# ATSAMRH71F20B register map
Vendor: Microchip Technology; Series: SAMRH71; File version: 0
Microchip ATSAMRH71F20B Microcontroller
CPU: CM7 r1p1, little endian, MPU, FPU, 3 interrupt priority bits
Registers are 32-bit, read-write, reset 0x0 unless marked. A register's access mark holds for its fields unless they carry their own. Offsets are from the block's base; lines under a group give offsets from that group; [hi:lo] are bit positions; {n}, {i} and the like mark numbered series; 'fields as' and 'values as' point back to an identical list; <NAME> marks a mode.

## Memory map
0x00000000 LOCKBIT size 0x4
0x40000000 MATRIX0 size 0x2CC — AHB Bus Matrix
0x40004000 HEFC size 0x194 — Harden Embedded Flash Controller
0x40008000 PIOA size 0x5E8 — Parallel Input/Output Controller
0x40008040 PIOB size 0x5E8
0x40008080 PIOC size 0x5E8
0x400080C0 PIOD size 0x5E8
0x40008100 PIOE size 0x5E8
0x40008140 PIOF size 0x5E8
0x40008180 PIOG size 0x5E8
0x4000C000 PMC size 0x1B8 — Power Management Controller
0x40010000 FLEXCOM0 size 0x6EC — Flexible Serial Communication
{0x40010000+0x4000*n} FLEXCOM{n} size 0x6EC (n=1..9)
0x40038000 QSPI size 0xEC — Quad Serial Peripheral Interface
0x4003C000 IP1553 size 0x54
0x40040000 SPW size 0xF0C
0x40058000 MCAN0 size 0xFC — Controller Area Network
0x4005C000 MCAN1 size 0xFC
0x40068000 PWM0 size 0x464 — Pulse Width Modulation Controller
0x4006C000 PWM1 size 0x464
0x40070000 TC0 size 0xE8 — Timer Counter
0x40074000 TC1 size 0xE8
0x40078000 TC2 size 0xE8
0x4007C000 TC3 size 0xE8
0x40080000 HEMC size 0x194
0x40081000 HSMC size 0x78 — Harden Static Memory Controller
0x40082000 HSDRAMC size 0x30 — Hardened SDRAM Controller
0x4008C000 ICM size 0xEC — Integrity Check Monitor
0x40090000 TRNG size 0x54 — True Random Number Generator
0x40094000 SHA size 0xEC — Secure Hash Algorithm
0x40098000 XDMAC size 0x13D8 — Extensible DMA Controller
0x4009C000 GMAC size 0x820 — Gigabit Ethernet MAC
0x400A0000 SFR size 0xA8 — Special Function Registers
0x400A8000 NMIC size 0xEC — Non-maskable Interrupt Controller
0x40100000 CHIPID size 0x8 — Chip Identifier
0x40100200 RSTC size 0xC — Reset Controller
0x40100210 SUPC size 0xD8 — Supply Controller
0x40100230 RTT size 0x10 — Real-time Timer
0x40100250 WDT size 0xC — Watchdog Timer
0x40100260 RTC size 0xD4 — Real-time Clock
0x40100300 WDT1 size 0xC
0x40100400 TCMECC size 0x24 — HECC
0x40100600 FLEXRAMECC size 0x20
0xE000E000 SCnSCB size 0xC — System control not in SCB
0xE000E010 SysTick size 0x10 — System timer
0xE000E100 NVIC size 0xE04 — Nested Vectored Interrupt Controller
0xE000ED00 SCB size 0x24C — System Control Block
0xE000ED90 MPU size 0x2C — Memory Protection Unit
0xE000EF30 FPU size 0x1C — Floating Point Unit

## Interrupts
0 SUPC
1 RSTC
2 RTC
3 RTT
4 WDT
5 PMC
6 MATRIX0
7 FLEXCOM0
8 FLEXCOM1
9 NMIC
10 PIOA
11 PIOB
12 PIOC
13 FLEXCOM2
14 FLEXCOM3
15 FLEXCOM4
16 PIOD
17 PIOE
18 CCW (SCB)
19 CCF (SCB)
20 FPU
21 IXC (FPU)
22 FLEXCOM5
23 FLEXCOM6
24 FLEXCOM7
25 TC0
26 TC1 (TC0)
27 TC2 (TC0)
28 TC3 (TC1)
29 TC4 (TC1)
30 TC5 (TC1)
31 PWM0
32 PWM1
33 ICM
34 PIOF
35 PIOG
36 MCAN0_INT0 (MCAN0)
37 MCAN0_INT1 (MCAN0)
38 MCAN1_INT0 (MCAN1)
39 MCAN1_INT1 (MCAN1)
40 TCMRAM_INTFIX (TCMECC)
41 TCMRAM_INTNOFIX (TCMECC)
42 FLEXRAM_INTFIX (FLEXRAMECC)
43 FLEXRAM_INTNOFIX (FLEXRAMECC)
44 SHA
45 FLEXCOM8
46 FLEXCOM9
47 WDT1
49 QSPI
50 HEFC_INT0 (HEFC)
51 HEFC_INTFIX (HEFC)
52 HEFC_INTNOFIX (HEFC)
53 TC6 (TC2)
54 TC7 (TC2)
55 TC8 (TC2)
56 TC9 (TC3)
57 TC10 (TC3)
58 TC11 (TC3)
59 HEMC_INTSDRAMC (HEMC)
60 HEMC_INTFIX (HEMC)
61 HEMC_INTNOFIX (HEMC)
62 SFR
63 TRNG
64 XDMAC
65 SPW_INT0 (SPW)
66 SPW_INT1 (SPW)
68 IP1553
69 GMAC
70 GMAC_Q1 (GMAC)
71 GMAC_Q2 (GMAC)
72 GMAC_Q3 (GMAC)
73 GMAC_Q4 (GMAC)
74 GMAC_Q5 (GMAC)

## CHIPID — Chip Identifier
Base 0x40100000; register names take the prefix CHIPID_
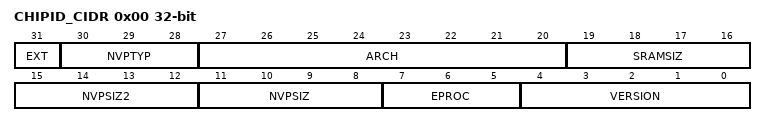
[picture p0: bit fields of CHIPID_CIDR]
0x00 CHIPID_CIDR ro — Chip ID Register
  [31] EXT — Extension Flag
  [30:28] NVPTYP — Nonvolatile Program Memory Type
    0=ROM; 1=ROMLESS (ROMless or on-chip Flash); 2=FLASH (Embedded Flash Memory); 3=ROM_FLASH (ROM and Embedded Flash Memory- NVPSIZ is ROM size- NVPSIZ2 is Flash size); 4=SRAM (SRAM emulating ROM)
  [27:20] ARCH — Architecture Identifier
    21=SAMU70SAMU71; 22=SAMV72
  [19:16] SRAMSIZ — Internal SRAM Size
    0=_48K (48 Kbytes); 1=_192K (192 Kbytes); 2=_384K (384 Kbytes); 3=_6K (6 Kbytes); 4=_24K (24 Kbytes); 5=_4K (4 Kbytes); 6=_80K (80 Kbytes); 7=_160K (160 Kbytes); 8=_8K (8 Kbytes); 9=_16K (16 Kbytes); 10=_32K (32 Kbytes); 11=_64K (64 Kbytes); 12=_128K (128 Kbytes); 13=_256K (256 Kbytes); 14=_96K (96 Kbytes); 15=_512K (512 Kbytes)
  [15:12] NVPSIZ2 — Second Nonvolatile Program Memory Size
    0=NONE; 1=_8K (8 Kbytes); 2=_16K (16 Kbytes); 3=_32K (32 Kbytes); 5=_64K (64 Kbytes); 7=_128K (128 Kbytes); 9=_256K (256 Kbytes); 10=_512K (512 Kbytes); 12=_1024K (1024 Kbytes); 14=_2048K (2048 Kbytes)
  [11:8] NVPSIZ — Nonvolatile Program Memory Size
    0=NONE; 1=_8K (8 Kbytes); 2=_16K (16 Kbytes); 3=_32K (32 Kbytes); 5=_64K (64 Kbytes); 7=_128K (128 Kbytes); 8=_160K (160 Kbytes); 9=_256K (256 Kbytes); 10=_512K (512 Kbytes); 12=_1024K (1024 Kbytes); 14=_2048K (2048 Kbytes)
  [7:5] EPROC — Embedded Processor
    0=SAMx7 (Cortex-M7); 1=ARM946ES; 2=ARM7TDMI; 3=CM3 (Cortex-M3); 4=ARM920T; 5=ARM926EJS; 6=CA5 (Cortex-A5); 7=CM4 (Cortex-M4)
  [4:0] VERSION — Version of the Device
0x04 CHIPID_EXID ro — Chip ID Extension Register
  [31:0] EXID — Chip ID Extension
    1=PACKAGE_TYPE_100 (100-lead package); 2=PACKAGE_TYPE_144 (144-lead package); 3=PACKAGE_TYPE_176 (176-lead package)

## Notices in the file
Copyright (c) 2017 Microchip Technology Inc.
SPDX-License-Identifier: Apache-2.0
Licensed under the Apache License, Version 2.0 (the "License");
you may not use this file except in compliance with the License.
You may obtain a copy of the License at
http://www.apache.org/licenses/LICENSE-2.0
Unless required by applicable law or agreed to in writing, software
distributed under the License is distributed on an "AS IS" BASIS,
WITHOUT WARRANTIES OR CONDITIONS OF ANY KIND, either express or implied.
See the License for the specific language governing permissions and
limitations under the License.
